# DISPC register map
Vendor: Texas Instruments
Registers are 32-bit, access per field, reset 0x0 unless marked. A register's access mark holds for its fields unless they carry their own. Offsets are as the file gives them; [hi:lo] are bit positions; {n}, {i} and the like mark numbered series; 'fields as' and 'values as' point back to an identical list.

## DISPC (part 5 of 6)
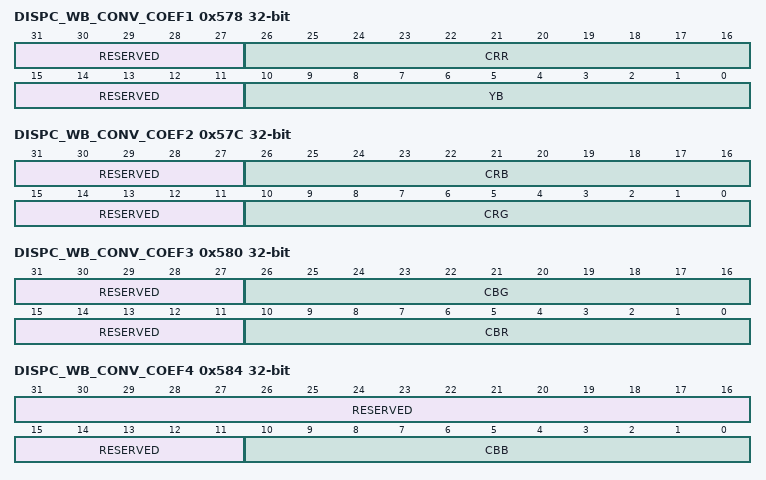
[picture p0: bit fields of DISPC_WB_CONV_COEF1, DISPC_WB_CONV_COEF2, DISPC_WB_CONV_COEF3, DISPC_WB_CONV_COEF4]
0x578 DISPC_WB_CONV_COEF1 — The register configures the color space conversion matrix coefficients for the write back pipeline. Shadow register, updated when.GOWB is set to 1 by software and current WB frame is finished (no more data in the write-back pipeline), when the WB pipeline is directly connected to one of the pipelines (graphics or video), combined with the synchronization event of the channel overlay output selected as an input to the WB pipeline (that is, VFP start period of primary LCD, or VFP start period of secondary LCD, or VFP start period of the third LCD, or EVSYNC), for all registers associated with the selected channel out and further delayed by the .WBDELAYCOUNT bit-field, for all registers of the Write back and DMA. In WB capture mode, both .GOWB and DISPC_CONTROL#.GOLCD/TV corresponding to the selected output channel shall be set. It is not required to set the GOWB bit when WB memory-to-memory mode is used.
  [31:27] RESERVED ro — Write 0s for future compatibility. Reads return 0.
  [26:16] CRR rw — CrR coefficient encoded signed value (from –1024 to 1023).
  [15:11] RESERVED ro — Write 0s for future compatibility. Reads return 0.
  [10:0] YB rw — YB coefficient encoded signed value (from –1024 to 1023).
0x57C DISPC_WB_CONV_COEF2 — The register configures the color space conversion matrix coefficients for the write back pipeline. Shadow register, updated when.GOWB is set to 1 by software and current WB frame is finished (no more data in the write-back pipeline), when the WB pipeline is directly connected to one of the pipelines (graphics or video), combined with the synchronization event of the channel overlay output selected as an input to the WB pipeline (that is, VFP start period of primary LCD, or VFP start period of secondary LCD, or VFP start period of the third LCD, or EVSYNC), for all registers associated with the selected channel out and further delayed by the .WBDELAYCOUNT bit-field, for all registers of the Write back and DMA. In WB capture mode, both .GOWB and DISPC_CONTROL#.GOLCD/TV corresponding to the selected output channel shall be set. It is not required to set the GOWB bit when WB memory-to-memory mode is used.
  [31:27] RESERVED ro — Write 0s for future compatibility. Reads return 0.
  [26:16] CRB rw — CrB coefficient encoded signed value (from –1024 to 1023).
  [15:11] RESERVED ro — Write 0s for future compatibility. Reads return 0.
  [10:0] CRG rw — CrG coefficient encoded signed value (from –1024 to 1023).
0x580 DISPC_WB_CONV_COEF3 — The register configures the color space conversion matrix coefficients for the write back pipeline. Shadow register, updated when.GOWB is set to 1 by software and current WB frame is finished (no more data in the write-back pipeline), when the WB pipeline is directly connected to one of the pipelines (graphics or video), combined with the synchronization event of the channel overlay output selected as an input to the WB pipeline (that is, VFP start period of primary LCD, or VFP start period of secondary LCD, or VFP start period of the third LCD, or EVSYNC), for all registers associated with the selected channel out and further delayed by the .WBDELAYCOUNT bit-field, for all registers of the Write back and DMA. In WB capture mode, both .GOWB and DISPC_CONTROL#.GOLCD/TV corresponding to the selected output channel shall be set. It is not required to set the GOWB bit when WB memory-to-memory mode is used.
  [31:27] RESERVED ro — Write 0s for future compatibility. Reads return 0.
  [26:16] CBG rw — CbG coefficient encoded signed value (from –1024 to 1023).
  [15:11] RESERVED ro — Write 0s for future compatibility. Reads return 0.
  [10:0] CBR rw — CbR coefficient encoded signed value (from –1024 to 1023).
0x584 DISPC_WB_CONV_COEF4 — The register configures the color space conversion matrix coefficients for the write back pipeline. Shadow register, updated when.GOWB is set to 1 by software and current WB frame is finished (no more data in the write-back pipeline), when the WB pipeline is directly connected to one of the pipelines (graphics or video), combined with the synchronization event of the channel overlay output selected as an input to the WB pipeline (that is, VFP start period of primary LCD, or VFP start period of secondary LCD, or VFP start period of the third LCD, or EVSYNC), for all registers associated with the selected channel out and further delayed by the .WBDELAYCOUNT bit-field, for all registers of the Write back and DMA. In WB capture mode, both .GOWB and DISPC_CONTROL#.GOLCD/TV corresponding to the selected output channel shall be set. It is not required to set the GOWB bit when WB memory-to-memory mode is used.
  [31:11] RESERVED ro — Write 0s for future compatibility. Reads return 0.
  [10:0] CBB rw — CbB coefficient encoded signed value (from –1024 to 1023).
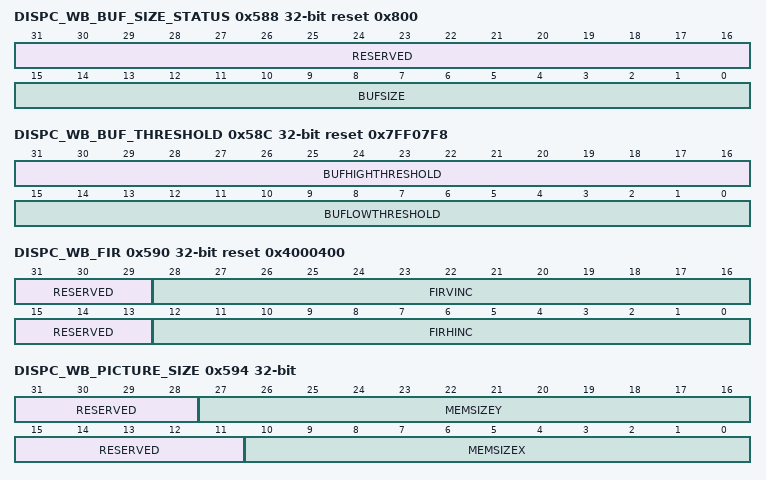
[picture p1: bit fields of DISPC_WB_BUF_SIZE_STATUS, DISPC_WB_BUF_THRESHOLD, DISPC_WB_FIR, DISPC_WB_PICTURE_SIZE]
0x588 DISPC_WB_BUF_SIZE_STATUS ro reset 0x800 — The register defines the DMA buffer size for the write back pipeline.
  [31:16] RESERVED — Write 0s for future compatibility. Reads return 0.
  [15:0] BUFSIZE — DMA buffer Size in number of 128 bits
0x58C DISPC_WB_BUF_THRESHOLD rw reset 0x7FF07F8 — The register configures the DMA buffer associated with the write-back pipeline. Shadow register, updated when.GOWB is set to 1 by software and current WB frame is finished (no more data in the write-back pipeline), when the WB pipeline is directly connected to one of the pipelines (graphics or video), combined with the synchronization event of the channel overlay output selected as an input to the WB pipeline (that is, VFP start period of primary LCD, or VFP start period of secondary LCD, or VFP start period of the third LCD, or EVSYNC), for all registers associated with the selected channel out and further delayed by the .WBDELAYCOUNT bit-field, for all registers of the Write back and DMA. In WB capture mode, both .GOWB and DISPC_CONTROL#.GOLCD/TV corresponding to the selected output channel shall be set. It is not required to set the GOWB bit when WB memory-to-memory mode is used.
  [31:16] BUFHIGHTHRESHOLD — DMA buffer high threshold number of 128 bits defining the threshold value
  [15:0] BUFLOWTHRESHOLD — DMA buffer low threshold number of 128 bits defining the threshold value
0x590 DISPC_WB_FIR reset 0x4000400 — The register configures the resize factors for horizontal and vertical up/downsampling of the write back pipeline. It is used for ARGB and Y setting. Shadow register, updated when.GOWB is set to 1 by software and current WB frame is finished (no more data in the write-back pipeline), when the WB pipeline is directly connected to one of the pipelines (graphics or video), combined with the synchronization event of the channel overlay output selected as an input to the WB pipeline (that is, VFP start period of primary LCD, or VFP start period of secondary LCD, or VFP start period of the third LCD, or EVSYNC), for all registers associated with the selected channel out and further delayed by the .WBDELAYCOUNT bit-field, for all registers of the Write back and DMA. In WB capture mode, both .GOWB and DISPC_CONTROL#.GOLCD/TV corresponding to the selected output channel shall be set. It is not required to set the GOWB bit when WB memory-to-memory mode is used.
  [31:29] RESERVED ro — Write 0s for future compatibility. Reads return 0.
  [28:16] FIRVINC rw — Vertical increment of the up/downsampling filter Encoded value (from 1 to 4096). The value 0 is invalid. The values greater than 4096 are invalid.
  [15:13] RESERVED ro — Write 0s for future compatibility. Reads return 0.
  [12:0] FIRHINC rw — Horizontal increment of the up/downsampling filter Encoded value (from 1 to 4096). The value 0 is invalid. The values greater than 4096 are invalid.
0x594 DISPC_WB_PICTURE_SIZE — The register configures the size of the write-back picture associated with the write back pipeline after up/down-scaling. Shadow register, updated when.GOWB is set to 1 by software and current WB frame is finished (no more data in the write-back pipeline), when the WB pipeline is directly connected to one of the pipelines (graphics or video), combined with the synchronization event of the channel overlay output selected as an input to the WB pipeline (that is, VFP start period of primary LCD, or VFP start period of secondary LCD, or VFP start period of the third LCD, or EVSYNC), for all registers associated with the selected channel out and further delayed by the .WBDELAYCOUNT bit-field, for all registers of the Write back and DMA. In WB capture mode, both .GOWB and DISPC_CONTROL#.GOLCD/TV corresponding to the selected output channel shall be set. It is not required to set the GOWB bit when WB memory-to-memory mode is used.
  [31:28] RESERVED ro — Write 0s for future compatibility. Reads return 0.
  [27:16] MEMSIZEY rw — Number of lines of the wb picture in memory. Encoded value (from 1 to 4096) to specify the number of lines of the picture in memory (program to value minus 1).
  [15:11] RESERVED ro — Write 0s for future compatibility. Reads return 0.
  [10:0] MEMSIZEX rw — Number of pixels of the wb picture in memory. Encoded value (from 1 to 2048) to specify the number of pixels of the picture in memory (program to value minus 1).
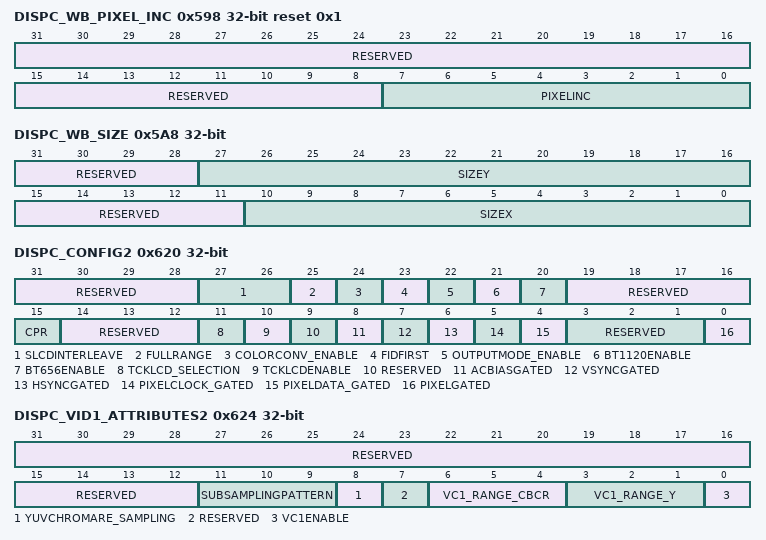
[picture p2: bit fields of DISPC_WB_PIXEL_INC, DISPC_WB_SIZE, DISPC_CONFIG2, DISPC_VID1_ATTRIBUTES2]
0x598 DISPC_WB_PIXEL_INC reset 0x1 — The register configures the number of bytes to increment between two pixels for the buffer associated with the write back pipeline. The register is used only when the TILER is not present in the system in order to perform low performance rotation. When the TILER IP is present it is highly recommended to use it for performing the rotation. Shadow register, updated when.GOWB is set to 1 by software and current WB frame is finished (no more data in the write-back pipeline), when the WB pipeline is directly connected to one of the pipelines (graphics or video), combined with the synchronization event of the channel overlay output selected as an input to the WB pipeline (that is, VFP start period of primary LCD, or VFP start period of secondary LCD, or VFP start period of the third LCD, or EVSYNC), for all registers associated with the selected channel out and further delayed by the .WBDELAYCOUNT bit-field, for all registers of the Write back and DMA. In WB capture mode, both .GOWB and DISPC_CONTROL#.GOLCD/TV corresponding to the selected output channel shall be set. It is not required to set the GOWB bit when WB memory-to-memory mode is used.
  [31:8] RESERVED ro — Write 0s for future compatibility. Reads return 0.
  [7:0] PIXELINC rw — Values other than 1 are invalid
0x5A4 DISPC_WB_ROW_INC rw reset 0x1 — The register configures the number of bytes to increment at the end of the row for the buffer associated with the vwrite back pipeline. Shadow register, updated when.GOWB is set to 1 by software and current WB frame is finished (no more data in the write-back pipeline), when the WB pipeline is directly connected to one of the pipelines (graphics or video), combined with the synchronization event of the channel overlay output selected as an input to the WB pipeline (that is, VFP start period of primary LCD, or VFP start period of secondary LCD, or VFP start period of the third LCD, or EVSYNC), for all registers associated with the selected channel out and further delayed by the .WBDELAYCOUNT bit-field, for all registers of the Write back and DMA. In WB capture mode, both .GOWB and DISPC_CONTROL#.GOLCD/TV corresponding to the selected output channel shall be set. It is not required to set the GOWB bit when WB memory-to-memory mode is used.
  [31:0] ROWINC — Number of bytes to increment at the end of the row Encoded signed value (from 21 to 2) to specify the number of bytes to increment at the end of the row in the video buffer. The value 0 is invalid. The value 1 means next pixel. The value 1 + n *bpp means increment of n pixels. The value 1 (n + 1) * bpp means decrement of n pixels.
0x5A8 DISPC_WB_SIZE — The register configures the size of the output of overlay connected to the write-back pipeline when the overlay output is only used by the write-back pipeline. When the overlay is output on the primary LCD or secondary LCD or TV outputs, the size of the frame is defined in the, , and respectively. Shadow register, updated when .GOWB is set to 1 by software and current WB frame is finished (no more data in the write-back pipeline), when the WB pipeline is directly connected to one of the pipelines (graphics or video), combined with the synchronization event of the channel overlay output selected as an input to the WB pipeline (that is, VFP start period of primary LCD, or VFP start period of secondary LCD, or VFP start period of the third LCD, or EVSYNC), for all registers associated with the selected channel out and further delayed by the .WBDELAYCOUNT bit-field, for all registers of the Write back and DMA. In WB capture mode, both .GOWB and DISPC_CONTROL#.GOLCD/TV corresponding to the selected output channel shall be set. It is not required to set the GOWB bit when WB memory-to-memory mode is used.
  [31:28] RESERVED ro — Write 0s for future compatibility. Reads return 0.
  [27:16] SIZEY rw — Number of lines of the Write-back picture Encoded value (from 1 to 4096) to specify the number of lines of the write-back picture from overlay or pipeline. Program to value minus 1.
  [15:11] RESERVED ro — Write 0s for future compatibility. Reads return 0.
  [10:0] SIZEX rw — Number of pixels of the Write-back picture Encoded value (from 1 to 2048) to specify the number of pixels of the write-back picture from overlay or pipeline. Program to value minus 1.
0x600 DISPC_VID1_BA_UV_j_0 rw — The register configures the base address of the UV buffer for the video window 1. (DISPC_VID1_BA_UV_0 and DISPC_VID1_BA_UV_1 for ping-pong mechanism with external trigger, based on the field polarity otherwise only DISPC_VID1_BA_UV_0 is used)). Shadow register, updated on VFP start period of primary LCD or VFP start period of the secondary LCD or VFP start period of the third LCD or EVSYNC or when.GOWB is set to 1 by software and current WB frame is finished (no more data in the write-back pipeline). The synchronization event is defined based on the output using the pipeline: primary LCD, secondary LCD, third LCD, TV output or write-back to the memory
  [31:0] BA — Video base address aligned on 16-bit boundary Base address of the UV video buffer used only in case of YUV4:2:0-NV12 When the TILER is addressed, the bits: [28:27] = 0x0 for 8-bit tiled [28:27] = 0x1 for 16-bit tiled [28:27] = 0x2 for 32-bit tiled [28:27] = 0x3 for page mode [31:29] = 0x0 for 0-degree view [31:29] = 0x1 for 180-degree view + mirroring [31:29] = 0x2 for 0-degree view + mirroring [31:29] = 0x3 for 180-degree view [31:29] = 0x4 for 270-degree view + mirroring [31:29] = 0x5 for 270-degree view [31:29] = 0x6 for 90-degree view [31:29] = 0x7 for 90-degree view + mirroring Otherwise the bits indicated the corresponding bit address to access the SDRAM.
0x604 DISPC_VID1_BA_UV_j_1 rw — The register configures the base address of the UV buffer for the video window 1. (DISPC_VID1_BA_UV_0 and DISPC_VID1_BA_UV_1 for ping-pong mechanism with external trigger, based on the field polarity otherwise only DISPC_VID1_BA_UV_0 is used)). Shadow register, updated on VFP start period of primary LCD or VFP start period of the secondary LCD or VFP start period of the third LCD or EVSYNC or when.GOWB is set to 1 by software and current WB frame is finished (no more data in the write-back pipeline). The synchronization event is defined based on the output using the pipeline: primary LCD, secondary LCD, third LCD, TV output or write-back to the memory
  fields as DISPC_VID1_BA_UV_j_0
0x608 DISPC_VID2_BA_UV_j_0 rw — The register configures the base address of the UV buffer for the video window 2. (DISPC_VID2_BA_UV_0 and DISPC_VID2_BA_UV_1 for ping-pong mechanism with external trigger, based on the field polarity otherwise only DISPC_VID2_BA_UV_0 is used)). Shadow register, updated on VFP start period of primary LCD or VFP start period of the secondary LCD or VFP start period of the third LCD or EVSYNC or when.GOWB is set to 1 by software and current WB frame is finished (no more data in the write-back pipeline). The synchronization event is defined based on the output using the pipeline: primary LCD, secondary LCD, third LCD, TV output or write-back to the memory
  fields as DISPC_VID1_BA_UV_j_0
0x60C DISPC_VID2_BA_UV_j_1 rw — The register configures the base address of the UV buffer for the video window 2. (DISPC_VID2_BA_UV_0 and DISPC_VID2_BA_UV_1 for ping-pong mechanism with external trigger, based on the field polarity otherwise only DISPC_VID2_BA_UV_0 is used)). Shadow register, updated on VFP start period of primary LCD or VFP start period of the secondary LCD or VFP start period of the third LCD or EVSYNC or when.GOWB is set to 1 by software and current WB frame is finished (no more data in the write-back pipeline). The synchronization event is defined based on the output using the pipeline: primary LCD, secondary LCD, third LCD, TV output or write-back to the memory
  fields as DISPC_VID1_BA_UV_j_0
0x610 DISPC_VID3_BA_UV_j_0 rw — The register configures the base address of the UV buffer for the video window 3. (DISPC_VID3_BA_UV_0 and DISPC_VID3_BA_UV_1 for ping-pong mechanism with external trigger, based on the field polarity otherwise only DISPC_VID3_BA_UV_0 is used)). Shadow register, updated on VFP start period of primary LCD or VFP start period of the secondary LCD or VFP start period of the third LCD or EVSYNC or when.GOWB is set to 1 by software and current WB frame is finished (no more data in the write-back pipeline). The synchronization event is defined based on the output using the pipeline: primary LCD, secondary LCD, third LCD, TV output or write-back to the memory
  [31:0] BA — Video base address alinged on 16-bit boundary Base address of the UV video buffer used only in case of YUV4:2:0-NV12 When the TILER is addressed, the bits: [28:27] = 0x0 for 8-bit tiled [28:27] = 0x1 for 16-bit tiled [28:27] = 0x2 for 32-bit tiled [28:27] = 0x3 for page mode [31:29] = 0x0 for 0-degree view [31:29] = 0x1 for 180-degree view + mirroring [31:29] = 0x2 for 0-degree view + mirroring [31:29] = 0x3 for 180-degree view [31:29] = 0x4 for 270-degree view + mirroring [31:29] = 0x5 for 270-degree view [31:29] = 0x6 for 90-degree view [31:29] = 0x7 for 90-degree view + mirroring Otherwise the bits indicated the corresponding bit address to access the SDRAM.
0x614 DISPC_VID3_BA_UV_j_1 rw — The register configures the base address of the UV buffer for the video window 3. (DISPC_VID3_BA_UV_0 and DISPC_VID3_BA_UV_1 for ping-pong mechanism with external trigger, based on the field polarity otherwise only DISPC_VID3_BA_UV_0 is used)). Shadow register, updated on VFP start period of primary LCD or VFP start period of the secondary LCD or VFP start period of the third LCD or EVSYNC or when.GOWB is set to 1 by software and current WB frame is finished (no more data in the write-back pipeline). The synchronization event is defined based on the output using the pipeline: primary LCD, secondary LCD, third LCD, TV output or write-back to the memory
  fields as DISPC_VID3_BA_UV_j_0
0x618 DISPC_WB_BA_UV_j_0 rw — The register configures the base address of the UV buffer for the write-back pipeline. (DISPC_WB_BA_UV_0 and DISPC_WB_BA_UV_1 for ping-pong mechanism with external trigger, based on the field polarity otherwise only DISPC_WB_BA_UV_0 is used)). Shadow register, updated when.GOWB is set to 1 by software and current WB frame is finished (no more data in the write-back pipeline), when the WB pipeline is directly connected to one of the pipelines (graphics or video), combined with the synchronization event of the channel overlay output selected as an input to the WB pipeline (that is, VFP start period of primary LCD, or VFP start period of secondary LCD, or VFP start period of the third LCD, or EVSYNC), for all registers associated with the selected channel out and further delayed by the .WBDELAYCOUNT bit-field, for all registers of the Write back and DMA. In WB capture mode, both .GOWB and DISPC_CONTROL#.GOLCD/TV corresponding to the selected output channel shall be set. It is not required to set the GOWB bit when WB memory-to-memory mode is used.
  fields as DISPC_VID3_BA_UV_j_0
0x61C DISPC_WB_BA_UV_j_1 rw — The register configures the base address of the UV buffer for the write-back pipeline. (DISPC_WB_BA_UV_0 and DISPC_WB_BA_UV_1 for ping-pong mechanism with external trigger, based on the field polarity otherwise only DISPC_WB_BA_UV_0 is used)). Shadow register, updated when.GOWB is set to 1 by software and current WB frame is finished (no more data in the write-back pipeline), when the WB pipeline is directly connected to one of the pipelines (graphics or video), combined with the synchronization event of the channel overlay output selected as an input to the WB pipeline (that is, VFP start period of primary LCD, or VFP start period of secondary LCD, or VFP start period of the third LCD, or EVSYNC), for all registers associated with the selected channel out and further delayed by the .WBDELAYCOUNT bit-field, for all registers of the Write back and DMA. In WB capture mode, both .GOWB and DISPC_CONTROL#.GOLCD/TV corresponding to the selected output channel shall be set. It is not required to set the GOWB bit when WB memory-to-memory mode is used.
  fields as DISPC_VID3_BA_UV_j_0
0x620 DISPC_CONFIG2 — The control register configures the Display Controller module for the secondary LCD output. Shadow register, updated on VFP start period of secondary LCD or VFP start period of the third LCD or EVSYNC
  [31:28] RESERVED ro — Write 0s for future compatibility. Reads return 0.
  [27:26] SLCDINTERLEAVE rw — sLCD Interleave Pattern
  [25] FULLRANGE rw — Color space conversion full range setting.
    0=Limrange (Limited range selected.); 1=Full range selected
  [24] COLORCONV_ENABLE rw — Enable the color space conversion. It shall be reset when CPR bit field is set to 0x1.
    0=ColSpCDis (Disable color space conversion RGB to YUV); 1=ColSpCEnb (Enable color space conversion RGB to YUV)
  [23] FIDFIRST rw — Selects the first field to output in case of interlace mode. In case of progressive mode, the value is not used.
    0=Even (First field is even.); 1=Odd (Odd field is first.)
  [22] OUTPUTMODE_ENABLE rw — Selects between progressive and interlace mode for the secondary LCD output.
    0=Disable (Progressive mode selected.); 1=Enable (Interlace mode selected.)
  [21] BT1120ENABLE rw — Selects BT.1120 format on the primary LCD output. It is not posssible to enable BT.656 and BT.1120 at the same time one the same LCD output. wr: VFP start of primary LCD
    0=BT.1120_is_disabled; 1=BT.1120_is_enabled
  [20] BT656ENABLE rw — Selects BT.656 format on the primary LCD output. It is not posssible to enable BT.656 and BT.1120 at the same time one the same LCD output. wr: VFP start of primary LCD
    0=BT.656_is_disabled; 1=BT.656_is_enabled
  [19:16] RESERVED ro — Write 0s for future compatibility. Reads return 0.
  [15] CPR rw — Color Phase Rotation Control secondary LCD output). It shall be reset when ColorConvEnable bit field is set to 1. wr: VFP start period of secondary LCD output
    0=CPRDis (Color phase rotation disabled); 1=CPREnb (Color phase rotation enabled)
  [14:12] RESERVED ro — Write 0s for future compatibility. Reads return 0.
  [11] TCKLCD_SELECTION rw — Transparency color key selection (secondary LCD output) wr: VFP start period of secondary LCD output
    0=GDTK (Destination transparency color key selected); 1=VSTK (Source transparency color key selected)
  [10] TCKLCDENABLE rw — Transparency color key enabled (secondary LCD output) wr: VFP start period of secondary LCD output
    0=DisTCK (Disable the transparency color key for the LCD); 1=EnbTCK (Enable the transparency color key for the LCD)
  [9] RESERVED ro — Write 0s for future compatibility. Reads return 0.
  [8] ACBIASGATED rw — ACBias gated enabled (secondary LCD output) wr: VFP start period of secondary LCD output
    0=ACBGDis (AcBias gated disabled); 1=ACBGEnb (AcBias gated enabled)
  [7] VSYNCGATED rw — VSYNC gated enabled (secondary LCD output) wr: VFP start period of secondary LCD output
    0=VGDis (VSYNC gated disabled); 1=VGEnb (VSYNC gated enabled)
  [6] HSYNCGATED rw — HSYNC gated enabled (secondary LCD output) wr: VFP start period of secondary LCD output
    0=HGDis (HSYNC gated disabled); 1=HGEnb (HSYNC gated enabled)
  [5] PIXELCLOCK_GATED rw — Pixel clock gated enabled (secondary LCD output) wr: VFP start period of secondary LCD output
    0=PCGDis (Pixel clock gated disabled); 1=PCGEnb (Pixel clock gated enabled)
  [4] PIXELDATA_GATED rw — Pixel data gated enabled (secondary LCD output) wr: VFP start period of secondary LCD output
    0=PDGDis (Pixel data gated disabled); 1=PDGEnb (Pixel data gated enabled)
  [3:1] RESERVED ro — Write 0s for future compatibility. Reads return 0.
  [0] PIXELGATED rw — Pixel gated enable (only for active matrix) (secondary LCD output) wr: VFP start period of secondary LCD output
    0=PclkTogA (Pixel clock always toggles (only in active matrix mode).); 1=PclkTogV (Pixel clock only toggles when there is valid data to display (only in active matrix mode).)
0x624 DISPC_VID1_ATTRIBUTES2 — The register configures the attributes of the video window 1. Shadow register, updated on VFP start period of primary LCD or VFP start period of the secondary LCD or VFP start period of the third LCD or EVSYNC or when.GOWB is set to 1 by software and current WB frame is finished (no more data in the write-back pipeline). The synchronization event is defined based on the output using the pipeline: primary LCD, secondary LCD, third LCD, TV output or write-back to the memory
  [31:12] RESERVED ro — Write 0s for future compatibility. Reads return 0.
  [11:9] SUBSAMPLINGPATTERN rw — Subsampling pattern setting.
  [8] YUVCHROMARE_SAMPLING rw — The YUV chrominance can be resampled using averaging of the adjacent chrominance samples, without using the polyphase filter for 4:2:2 input or can be calculated using the polyphase filter for 4:2:2/4:2:0. The polyphase filter is mandatory for the 4:2:0 format. This bit controls the order in which the processing is done on the video pipe.
    0=Average (When input is 4:2:2, the missing chrominance samples are calculated by averaging the adjacent samples if. ROTATION=0 only. Other rotation configurations are not supported.); 1=Filter (For 4:2:2 (or 4:2:0), the missing chrominance samples are calculated by filtering the adjacent samples (5-tap polyphase filter). See, Configuration 2: Video Pipeline. All rotation configurations are supported.)
  [7] RESERVED ro — Write 0s for future compatibility. Reads return 0.
  [6:4] VC1_RANGE_CBCR rw — Defines the VC-1 range value for the CbCr component from 0 to 7.
  [3:1] VC1_RANGE_Y rw — Defines the VC-1 range value for the Y component from 0 to 7.
  [0] VC1ENABLE rw — Enable/disable the VC-1 range mapping processing. The bit field is ignored if the format is not one of the supported YUV formats.
    0=VC1Dis (VC-1 range mapping disabled); 1=VC1Enb (VC-1 range mapping enabled)
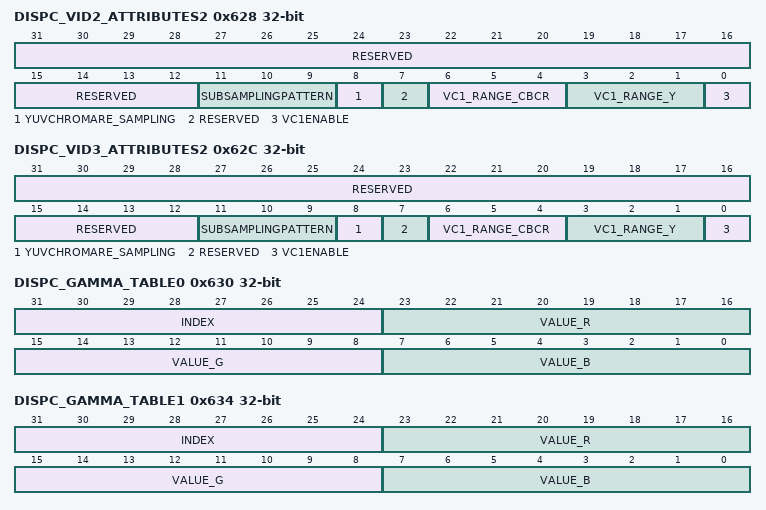
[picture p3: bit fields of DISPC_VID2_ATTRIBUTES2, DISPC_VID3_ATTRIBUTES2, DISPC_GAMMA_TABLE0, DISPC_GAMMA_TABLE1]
0x628 DISPC_VID2_ATTRIBUTES2 — The register configures the attributes of the video window 2. Shadow register, updated on VFP start period of primary LCD or VFP start period of the secondary LCD or VFP start period of the third LCD or EVSYNC or when.GOWB is set to 1 by software and current WB frame is finished (no more data in the write-back pipeline). The synchronization event is defined based on the output using the pipeline: primary LCD, secondary LCD, third LCD, TV output or write-back to the memory
  [31:12] RESERVED ro — Write 0s for future compatibility. Reads return 0.
  [11:9] SUBSAMPLINGPATTERN rw — Subsampling pattern setting.
  [8] YUVCHROMARE_SAMPLING rw — The YUV chrominance can be resampled using averaging of the adjacent chrominance samples, without using the polyphase filter for 4:2:2 input or can be calculated using the polyphase filter for 4:2:2/4:2:0. The polyphase filter is mandatory for the 4:2:0 format. This bit controls the order in which the processing is done on the video pipe.
    0=Average (When input is in 4:2:2, the missing chrominance samples are calculated by averaging the adjacent samples if. ROTATION=0 only. Other rotation configurations are not supported.); 1=Filter (For 4:2:2 (or 4:2:0), the missing chrominance samples are calculated by filtering the adjacent samples (5-tap polyphase filter). See, Configuration 2: Video Pipeline. All rotation configurations are supported.)
  [7] RESERVED ro — Write 0s for future compatibility. Reads return 0.
  [6:4] VC1_RANGE_CBCR rw — Defines the VC-1 range value for the CbCr component from 0 to 7.
  [3:1] VC1_RANGE_Y rw — Defines the VC-1 range value for the Y component from 0 to 7.
  [0] VC1ENABLE rw — Enable/disable the VC-1 range mapping processing. The bit field is ignored if the format is not one of the supported YUV formats.
    values as DISPC_VID1_ATTRIBUTES2.VC1ENABLE
0x62C DISPC_VID3_ATTRIBUTES2 — The register configures the attributes of the video window 3. Shadow register, updated on VFP start period of primary LCD or VFP start period of the secondary LCD or VFP start period of the third LCD or EVSYNC or when.GOWB is set to 1 by software and current WB frame is finished (no more data in the write-back pipeline). The synchronization event is defined based on the output using the pipeline: primary LCD, secondary LCD, third LCD, TV output or write-back to the memory
  fields as DISPC_VID2_ATTRIBUTES2
0x630 DISPC_GAMMA_TABLE0 wo — The register configures the look up table used as color look up table for BITMAP formats (1-, 2-, 4, and 8-bpp) on the graphics pipeline or as gamma table on the primary LCD output. NOTE: CLUT and BITMAP formats are not supported in this family of devices.
  [31:24] INDEX — Defines the location in the table where the bit field VALUE is stored.
  [23:16] VALUE_R — 8-bit value used to defined the value to store at the location in the table defined by the bit field INDEX
  [15:8] VALUE_G — 8-bit value used to defined the value to store at the location in the table defined by the bit field INDEX
  [7:0] VALUE_B — 8-bit value used to defined the value to store at the location in the table defined by the bit field INDEX
0x634 DISPC_GAMMA_TABLE1 wo — The register configures the gamma table on the secondary LCD output.
  fields as DISPC_GAMMA_TABLE0
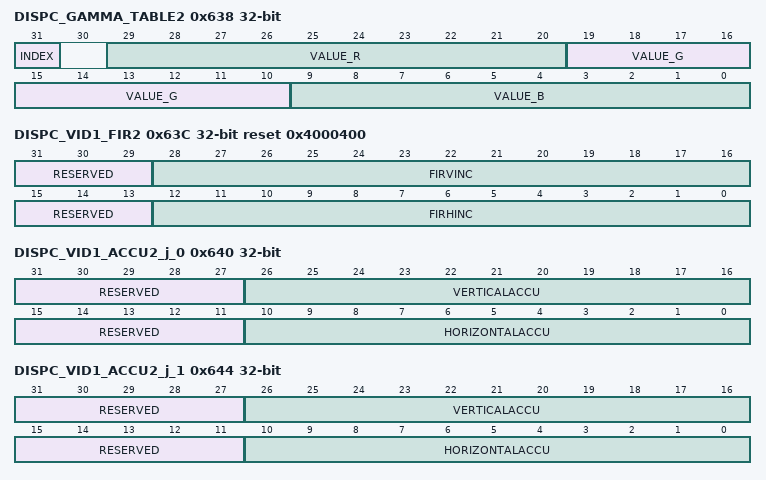
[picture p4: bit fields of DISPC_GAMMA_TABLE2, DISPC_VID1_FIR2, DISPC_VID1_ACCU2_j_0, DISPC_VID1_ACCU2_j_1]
0x638 DISPC_GAMMA_TABLE2 wo — The register configures the gamma table on the TV output.
  [31] INDEX — Setting this bit to 1 resets the internal index counter to zero. Each subsequent access to the register (with the INDEX bit kept at 0) increments the address for the next storage location into the table memory.
  [29:20] VALUE_R — 10-bit color component value to store in the table
  [19:10] VALUE_G — 10-bit color component value to store in the table
  [9:0] VALUE_B — 10-bit color component value to store in the table
0x63C DISPC_VID1_FIR2 reset 0x4000400 — The register configures the resize factors for horizontal and vertical up/downsampling of the video window 1. It is used for Crb and Cr setting. It is used only when the pixel format at the input of the filter is one of the YUV formats. If the pixel format at the input of the filter is ARGB (all ARGB, RGB, RGBA are converted to ARGB32-8888 by the color space conversion before going to the filter is the color space conversion is done before the filter). When the register is not used by the hardware, any value can be used for the bit fields. Shadow register, updated on VFP start period of primary LCD or VFP start period of the secondary LCD or VFP start period of the third LCD or EVSYNC or when.GOWB is set to 1 by software and current WB frame is finished (no more data in the write-back pipeline). The synchronization event is defined based on the output using the pipeline: primary LCD, secondary LCD, third LCD, TV output or write-back to the memory
  [31:29] RESERVED ro — Write 0s for future compatibility. Reads return 0.
  [28:16] FIRVINC rw — Vertical increment of the up/downsampling filter for Cb and Cr. Encoded value (from 1 to 4096). The value 0 is invalid. The values greater than 4096 are invalid.
  [15:13] RESERVED ro — Write 0s for future compatibility. Reads return 0.
  [12:0] FIRHINC rw — Horizontal increment of the up/downsampling filter for Cb and Cr. Encoded value (from 1 to 4096). The value 0 is invalid. The values greater than 4096 are invalid.
0x640 DISPC_VID1_ACCU2_j_0 — The register configures the resize accumulator init values for horizontal and vertical up/downsampling of the video window 1 (DISPC_VID1_ACCU2_0 and DISPC_VID1_ACCU2_1 for ping-pong mechanism with external trigger, based on the field polarity) It is used for Cb and Cr setting. It is used only when the pixel format at the input of the filter is one of the YUV formats. If the pixel format at the input of the filter is ARGB (all ARGB, RGB, RGBA are converted to ARGB32-8888 by the color space conversion before going to the filter is the color space conversion is done before the filter). When the register is not used by the hardware, any value can be used for the bit fields. Shadow register, updated on VFP start period of primary LCD or VFP start period of the secondary LCD or VFP start period of the third LCD or EVSYNC or when.GOWB is set to 1 by software and current WB frame is finished (no more data in the write-back pipeline). The synchronization event is defined based on the output using the pipeline: primary LCD, secondary LCD, third LCD, TV output or write-back to the memory
  [31:27] RESERVED ro — Write 0s for future compatibility. Reads return 0.
  [26:16] VERTICALACCU rw — Vertical initialization accu value Encoded value (from –1024 to 1023).
  [15:11] RESERVED ro — Write 0s for future compatibility. Reads return 0.
  [10:0] HORIZONTALACCU rw — Horizontal initialization accu value Encoded value (from –1024 to 1023).
0x644 DISPC_VID1_ACCU2_j_1 — The register configures the resize accumulator init values for horizontal and vertical up/downsampling of the video window 1 (DISPC_VID1_ACCU2_0 and DISPC_VID1_ACCU2_1 for ping-pong mechanism with external trigger, based on the field polarity) It is used for Cb and Cr setting. It is used only when the pixel format at the input of the filter is one of the YUV formats. If the pixel format at the input of the filter is ARGB (all ARGB, RGB, RGBA are converted to ARGB32-8888 by the color space conversion before going to the filter is the color space conversion is done before the filter). When the register is not used by the hardware, any value can be used for the bit fields. Shadow register, updated on VFP start period of primary LCD or VFP start period of the secondary LCD or VFP start period of the third LCD or EVSYNC or when.GOWB is set to 1 by software and current WB frame is finished (no more data in the write-back pipeline). The synchronization event is defined based on the output using the pipeline: primary LCD, secondary LCD, third LCD, TV output or write-back to the memory
  fields as DISPC_VID1_ACCU2_j_0
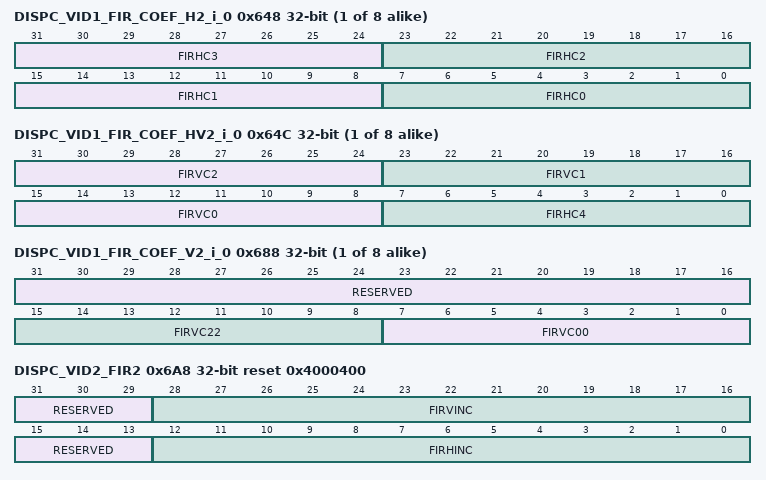
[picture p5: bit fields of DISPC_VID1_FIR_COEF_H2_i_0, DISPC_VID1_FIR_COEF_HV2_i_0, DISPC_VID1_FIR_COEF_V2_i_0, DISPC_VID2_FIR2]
{0x648+8i} DISPC_VID1_FIR_COEF_H2_i_{i} rw (i=0..7) — The bank of registers configure the up/down-scaling coefficients for the horizontal resize of the video picture associated with the video window 1 for the phases from 0 to 7. It is used for Crb and Cr setting. It is used only when the pixel format at the input of the filter is one of the YUV formats. If the pixel format at the input of the filter is ARGB (all ARGB, RGB, RGBA are converted to ARGB32-8888 by the color space conversion before going to the filter is the color space conversion is done before the filter). When the register is not used by the hardware, any value can be used for the bit fields. Shadow register, updated on VFP start period of primary LCD or VFP start period of the secondary LCD or VFP start period of the third LCD or EVSYNC or when.GOWB is set to 1 by software and current WB frame is finished (no more data in the write-back pipeline). The synchronization event is defined based on the output using the pipeline: primary LCD, secondary LCD, third LCD, TV output or write-back to the memory
  [31:24] FIRHC3 — Signed coefficient C3 for the horizontal up/down-scaling with the phase n
  [23:16] FIRHC2 — Unsigned coefficient C2 for the horizontal up/down-scaling with the phase n
  [15:8] FIRHC1 — Signed coefficient C1 for the horizontal up/down-scaling with the phase n
  [7:0] FIRHC0 — Signed coefficient C0 for the horizontal up/down-scaling with the phase n
{0x64C+8i} DISPC_VID1_FIR_COEF_HV2_i_{i} rw (i=0..7) — The bank of registers configure the down/up/down-scaling coefficients for the vertical and horizontal resize of the video picture associated with the video window 1 for the phases from 0 to 7. It is used for Crb and Cr setting. It is used only when the pixel format at the input of the filter is one of the YUV formats. If the pixel format at the input of the filter is ARGB (all ARGB, RGB, RGBA are converted to ARGB32-8888 by the color space conversion before going to the filter is the color space conversion is done before the filter). When the register is not used by the hardware, any value can be used for the bit fields. Shadow register, updated on VFP start period of primary LCD or VFP start period of the secondary LCD or VFP start period of the third LCD or EVSYNC or when.GOWB is set to 1 by software and current WB frame is finished (no more data in the write-back pipeline). The synchronization event is defined based on the output using the pipeline: primary LCD, secondary LCD, third LCD, TV output or write-back to the memory
  [31:24] FIRVC2 — Signed coefficient C2 for the vertical up/down-scaling with the phase n
  [23:16] FIRVC1 — Unsigned coefficient C1 for the vertical up/down-scaling with the phase n
  [15:8] FIRVC0 — Signed coefficient C0 for the vertical up/down-scaling with the phase n
  [7:0] FIRHC4 — Signed coefficient C4 for the horizontal up/down-scaling with the phase n
{0x688+4i} DISPC_VID1_FIR_COEF_V2_i_{i} (i=0..7) — The bank of registers configure the down/up/down-scaling coefficients for the vertical resize of the video picture associated with the video window 1 for the phases from 0 to 7. It is used for Crb and Cr setting. It is used only when the pixel format at the input of the filter is one of the YUV formats. If the pixel format at the input of the filter is ARGB (all ARGB, RGB, RGBA are converted to ARGB32-8888 by the color space conversion before going to the filter is the color space conversion is done before the filter). When the register is not used by the hardware, any value can be used for the bit fields. Shadow register, updated on VFP start period of primary LCD or VFP start period of the secondary LCD or VFP start period of the third LCD or EVSYNC or when.GOWB is set to 1 by software and current WB frame is finished (no more data in the write-back pipeline). The synchronization event is defined based on the output using the pipeline: primary LCD, secondary LCD, third LCD, TV output or write-back to the memory
  [31:16] RESERVED ro — Write 0s for future compatibility. Reads return 0.
  [15:8] FIRVC22 rw — Signed coefficient C22 for the vertical up/down-scaling with the phase n
  [7:0] FIRVC00 rw — Signed coefficient C00 for the vertical up/down-scaling with the phase n
0x6A8 DISPC_VID2_FIR2 reset 0x4000400 — The register configures the resize factors for horizontal and vertical up/downsampling of the video window 2. It is used for Crb and Cr setting. It is used only when the pixel format at the input of the filter is one of the YUV formats. If the pixel format at the input of the filter is ARGB (all ARGB, RGB, RGBA are converted to ARGB32-8888 by the color space conversion before going to the filter is the color space conversion is done before the filter). When the register is not used by the hardware, any value can be used for the bit fields. Shadow register, updated on VFP start period of primary LCD or VFP start period of the secondary LCD or VFP start period of the third LCD or EVSYNC or when.GOWB is set to 1 by software and current WB frame is finished (no more data in the write-back pipeline). The synchronization event is defined based on the output using the pipeline: primary LCD, secondary LCD, third LCD, TV output or write-back to the memory
  fields as DISPC_VID1_FIR2
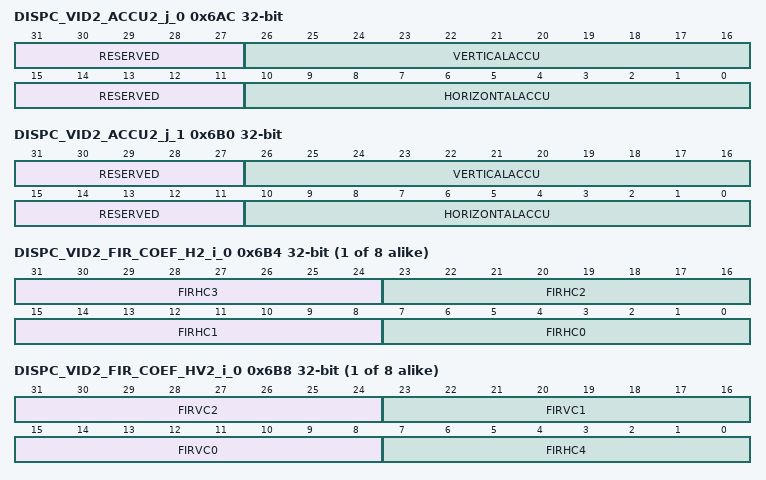
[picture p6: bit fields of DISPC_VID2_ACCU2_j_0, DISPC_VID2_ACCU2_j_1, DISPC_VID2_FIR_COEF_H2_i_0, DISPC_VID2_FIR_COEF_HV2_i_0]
0x6AC DISPC_VID2_ACCU2_j_0 — The register configures the resize accumulator init values for horizontal and vertical up/downsampling of the video window 2 (DISPC_VID2_ACCU2_0 and DISPC_VID2_ACCU2_1 for ping-pong mechanism with external trigger, based on the field polarity). It is used for Cb and Cr setting. It is used only when the pixel format at the input of the filter is one of the YUV formats. If the pixel format at the input of the filter is ARGB (all ARGB, RGB, RGBA are converted to ARGB32-8888 by the color space conversion before going to the filter is the color space conversion is done before the filter). When the register is not used by the hardware, any value can be used for the bit fields. Shadow register, updated on VFP start period of primary LCD or VFP start period of the secondary LCD or VFP start period of the third LCD or EVSYNC or when.GOWB is set to 1 by software and current WB frame is finished (no more data in the write-back pipeline). The synchronization event is defined based on the output using the pipeline: primary LCD, secondary LCD, third LCD, TV output or write-back to the memory
  fields as DISPC_VID1_ACCU2_j_0
0x6B0 DISPC_VID2_ACCU2_j_1 — The register configures the resize accumulator init values for horizontal and vertical up/downsampling of the video window 2 (DISPC_VID2_ACCU2_0 and DISPC_VID2_ACCU2_1 for ping-pong mechanism with external trigger, based on the field polarity). It is used for Cb and Cr setting. It is used only when the pixel format at the input of the filter is one of the YUV formats. If the pixel format at the input of the filter is ARGB (all ARGB, RGB, RGBA are converted to ARGB32-8888 by the color space conversion before going to the filter is the color space conversion is done before the filter). When the register is not used by the hardware, any value can be used for the bit fields. Shadow register, updated on VFP start period of primary LCD or VFP start period of the secondary LCD or VFP start period of the third LCD or EVSYNC or when.GOWB is set to 1 by software and current WB frame is finished (no more data in the write-back pipeline). The synchronization event is defined based on the output using the pipeline: primary LCD, secondary LCD, third LCD, TV output or write-back to the memory
  fields as DISPC_VID1_ACCU2_j_0
{0x6B4+8i} DISPC_VID2_FIR_COEF_H2_i_{i} rw (i=0..7) — The bank of registers configure the up/down-scaling coefficients for the horizontal resize of the video picture associated with the video window 2 for the phases from 0 to 7. It is used for Crb and Cr setting. It is used only when the pixel format at the input of the filter is one of the YUV formats. If the pixel format at the input of the filter is ARGB (all ARGB, RGB, RGBA are converted to ARGB32-8888 by the color space conversion before going to the filter is the color space conversion is done before the filter). When the register is not used by the hardware, any value can be used for the bit fields. Shadow register, updated on VFP start period of primary LCD or VFP start period of the secondary LCD or VFP start period of the third LCD or EVSYNC or when.GOWB is set to 1 by software and current WB frame is finished (no more data in the write-back pipeline). The synchronization event is defined based on the output using the pipeline: primary LCD, secondary LCD, third LCD, TV output or write-back to the memory
  fields as DISPC_VID1_FIR_COEF_H2_i_0
{0x6B8+8i} DISPC_VID2_FIR_COEF_HV2_i_{i} rw (i=0..7) — The bank of registers configure the down/up/down-scaling coefficients for the vertical and horizontal resize of the video picture associated with the video window 2 for the phases from 0 to 7. It is used for Crb and Cr setting. It is used only when the pixel format at the input of the filter is one of the YUV formats. If the pixel format at the input of the filter is ARGB (all ARGB, RGB, RGBA are converted to ARGB32-8888 by the color space conversion before going to the filter is the color space conversion is done before the filter). When the register is not used by the hardware, any value can be used for the bit fields. Shadow register, updated on VFP start period of primary LCD or VFP start period of the secondary LCD or VFP start period of the third LCD or EVSYNC or when.GOWB is set to 1 by software and current WB frame is finished (no more data in the write-back pipeline). The synchronization event is defined based on the output using the pipeline: primary LCD, secondary LCD, third LCD, TV output or write-back to the memory
  fields as DISPC_VID1_FIR_COEF_HV2_i_0
